# YTM32B1HA0 register map
Vendor: YTMicro; File version: 1.0
CPU: little endian, MPU, FPU, 2 interrupt priority bits
Registers are 32-bit, read-write, reset 0x0 unless marked. A register's access mark holds for its fields unless they carry their own. Offsets are from the block's base; [hi:lo] are bit positions; {n}, {i} and the like mark numbered series.

## pTMR0 — Periodic timer
Base 0x40168000; register names take the prefix pTMR0_
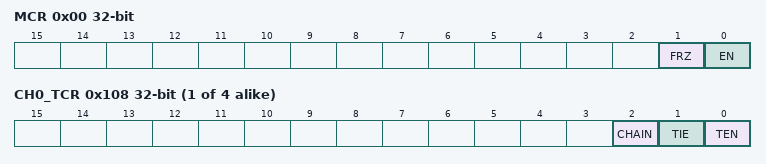
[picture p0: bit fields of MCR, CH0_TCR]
0x00 MCR
  [1] FRZ — Allows the timers to be stopped when the device enters debug mode.
    0=pTMR continues to run in debug mode; 1=pTMR stops in debug mode
  [0] EN — Enable pTMR module
    0=pTMR is disabled; 1=pTMR is enabled
{0x100+0x10*i} CH{i}_TSV (i=0..3) — Timer Start Value Register
  [31:0] STVAL — This register set the timer start value. The timer will count down until it reaches 0, then it will generate an interrupt and loads the value again. Writing a new value to this register will not restart the timer, instead the value will be loaded once the timer expires. To abort the current cycle and start a timer period with the new value, the timer must be disabled and enabled again.
{0x104+0x10*i} CH{i}_TCV (i=0..3) — Timer Current Value Register
  [31:0] CVAL — This register stands for current timer value when user read this register. The value of this register will be frozen in debug mode if MCR[FRZ] is set.
{0x108+0x10*i} CH{i}_TCR (i=0..3) — Timer Control Register
  [2] CHAIN — When setting this bit, it will link multi-channel in sequence to combine a new bits counter, it just links the front channel.
    0=Chaining is disabled, channel timer runs independently; 1=Chaining is enabled
  [1] TIE — Enable interrupt when setting this bit
    0=Disable timer interrupt of corresponding channel; 1=Enable timer interrupt of corresponding channel
  [0] TEN — Enable the timer of corresponding channel
    0=Disable the timer of corresponding channel; 1=Enable the timer of corresponding channel
{0x10C+0x10*i} CH{i}_TFR (i=0..3) — Timer Flag Register
  [0] TIF — Hardware will set this bit as 1 when timer interrupt is enabled, and writing logic 1 to this bit will clear this bit as 0.
    0=Timeout did not occur; 1=Timeout occurred

## pTMR1 — Periodic timer
Base 0x4016C000; register names take the prefix pTMR1_
Registers as pTMR0.

## pTMR2 — Periodic timer
Base 0x40170000; register names take the prefix pTMR2_
Registers as pTMR0.

## PCRC — Cyclic Redundancy Check
Base 0x40194000; register names take the prefix PCRC_
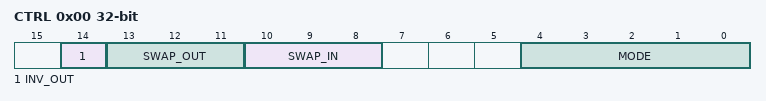
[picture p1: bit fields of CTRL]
0x00 CTRL
  [14] INV_OUT — Bit-inversion for all CRC output bits.
    0=Disable the bit-inversion; 1=Enable the bit-inversion
  [13:11] SWAP_OUT — Swap all the outputs bits for CRC output data. Please note that other register values will be no effect.
    0=Disable the output bit-swap; 1=Bit-swap in byte; 2=Bit-swap in word; 4=Byte-swap in word
  [10:8] SWAP_IN — Swap all the Inputs bits for CRC input data. Please note that other register values will be no effect.
    0=Disable the input bit-swap; 1=Bit-swap in byte; 2=Bit-swap in word; 4=Byte-swap in word
  [4:0] MODE — Set CRC calculation mode. User should be aware of the correct crc mode of programmed polynomial.
0x04 POLY
  [31:0] POLY — This register contains the programmable polynomial.
0x08 INIT
  [31:0] SEED — This register contains the CRC initial seed value.
0x0C IN32 wo
  [31:0] DATA rw — CRC data input in 32 bits
0x10 RESULT ro
  [31:0] RESULT rw — This register contains the result of CRC calculation. If bit-swap function is enabled, it may change the valid bits position, user should account for this situation.

## WDG — Watchdog module
Base 0x401A8000; register names take the prefix WDG_
0x00 SVCR wo — Watchdog Service Code Register
  [15:0] SVCODE — It can be used to service the watchdog or to clear the soft lock bit. Writing 0xB631 followed by 0xC278 will clear the soft lock bit, writing 0xA518 followed by 0xD826 to service the watchdog.
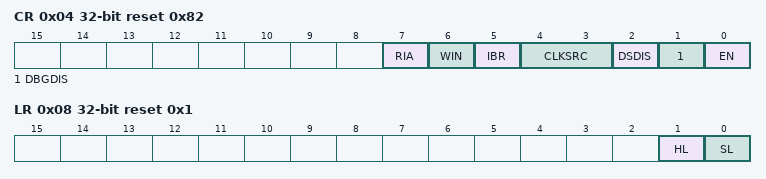
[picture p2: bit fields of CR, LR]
0x04 CR reset 0x82 — Watchdog Control Register
  [7] RIA — Enable reset for invalid APB access.
    0=Disable to generate reset by invalid APB access; 1=Enable to generate reset by invalid APB access
  [6] WIN — Enable window mode.
    0=Disable window mode, watchdog service can be done at any time; 1=Enable window mode, watchdog service is can only be done when timer value is less than the value of WIN register
  [5] IBR — Enable interrupt before reset function
    0=Disable interrupt before reset; 1=Enable interrupt before reset, when watchdog time-out, generate an interrupt first and when next time-out happens, generate reset
  [4:3] CLKSRC
    0=Functional clock from IPC; 1=Bus clock
  [2] DSDIS — Enable or disable watchdog in deepsleep mode
    0=Enable watchdog in deepsleep mode; 1=Disable watchdog in deepsleep mode
  [1] DBGDIS — Enable or disable watchdog in debug mode.
    0=Enable watchdog in debug mode; 1=Disable watchdog in debug mode
  [0] EN — Enable watchdog module.
    0=Disable watchdog module; 1=Enable watchdog module
0x08 LR reset 0x1 — Watchdog Lock Register
  [1] HL — Hard lock, when this bit set, the CR, WIN, TO are read-only. once set, the bit can only be clear by reset.
  [0] SL — Soft lock, when this bit set, the CR, WIN, TO are read-only. this bit can be clear by writing a valid sequence to SVR register.
0x0C TOVR reset 0x300 — Watchdog Timer Overflow Value
  [31:0] TO — A 32bit down counter uses this value to start count. Writing value should be greater than 0x100. Otherwise 0x100 is written to this register.
0x10 WVR
  [31:0] WIN — When CR[WIN] is set, the window mode is enabled, the service sequence can only be written when the timer value is less than the value of this register.
0x14 CNTCVR ro — Watchdog Counter Current Value Register
  [31:0] CVAL — Watchdog counter current value.
0x18 INTF — Watchdog Interrupt Flag register
  [0] IF — Watchdog interrupt flag. Write 1 to this field to clear the flag and interrupt.
    0=No watchdog interrupt is pending; 1=Watchdog timer time-out interrupt is pending

## INTM — Interrupt Monitor
Base 0x401C4000; register names take the prefix INTM_
0x00 GCTRL
  [0] GEN — The field is used to enable or disable all monitors
    0=interrupt monitor is disabled; 1=interrupt monitor is enabled
0x04 GINTACK reset 0xFF
  [7:0] SRC — This field is used to specify the interrupt request number to stop the TIMERn.
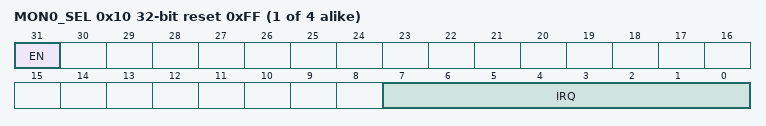
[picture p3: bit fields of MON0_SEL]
{0x10+0x10*i} MON{i}_SEL reset 0xFF (i=0..3)
  [31] EN — This field is used to enable or disable this monitor
  [7:0] IRQ — This field is used to select the monitored interrupt source
{0x14+0x10*i} MON{i}_THD reset 0xFFFFFF (i=0..3)
  [23:0] THRESHOLD — This field is used to configure the maximum number of INTM clock cycles allowed for the monitored interrupt request
{0x18+0x10*i} MON{i}_TMR (i=0..3)
  [23:0] CNT — This field is used to count the number of INTM clock cycles, up to 24 bits of resolution, write any value to reset the CNT.
{0x1C+0x10*i} MON{i}_STS ro (i=0..3)
  [0] OF rw — This field indicates whether MONn_TMR value has exceeded the MONn_THRESHOLD value
